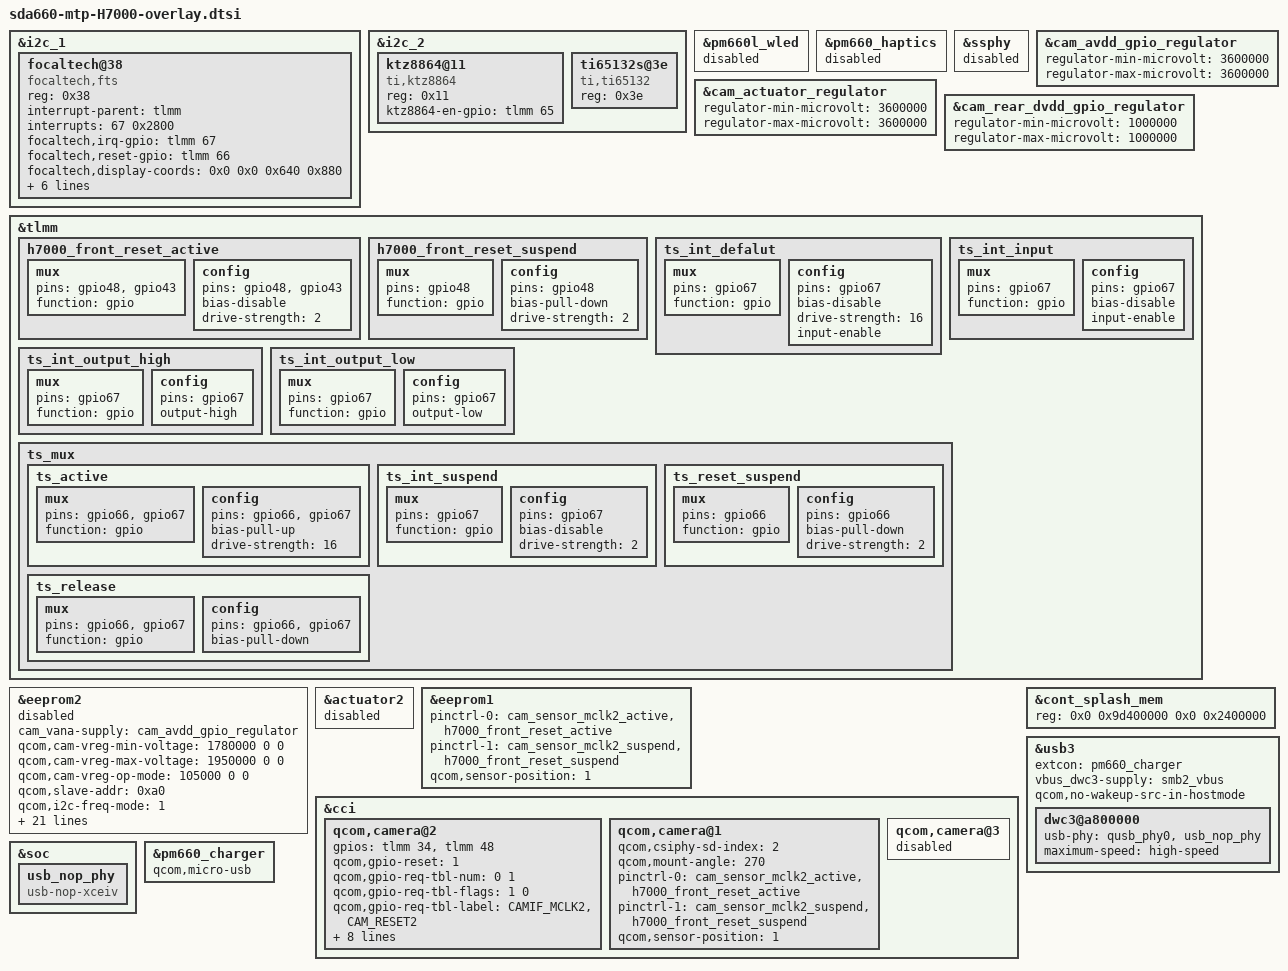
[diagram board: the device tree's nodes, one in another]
/*
 * SPDX-FileCopyrightText: The LineageOS Project
 * SPDX-License-Identifier: Apache-2.0
 */

#include "audio/sda660-audio-tfa98xxx.dtsi"
#include "battery/sda660-battery-H7000.dtsi"
#include "display/sda660-display-H7000.dtsi"

&i2c_1 {
	status = "ok";

	focaltech@38 {
		compatible = "focaltech,fts";
		reg = <0x38>;
		interrupt-parent = <&tlmm>;
		interrupts = <67 0x2800>;
		focaltech,irq-gpio = <&tlmm 67 0x2>;
		focaltech,reset-gpio = <&tlmm 66 0x0>;
		focaltech,display-coords = <0x0 0x0 0x640 0x880>;
		focaltech,max-touch-number = <10>;
		status = "okay";
		pinctrl-names = "pmx_ts_active", "pmx_ts_suspend", "pmx_ts_release";
		pinctrl-0 = <&ts_active>;
		pinctrl-1 = <&ts_int_suspend &ts_reset_suspend>;
		pinctrl-2 = <&ts_release>;
		vdd-supply = <&pm660l_l6>;
		vcc_i2c-supply = <&pm660_l13>;
	};
};

&i2c_2 {
	status = "ok";

	ktz8864@11 {
		compatible = "ti,ktz8864";
		reg = <0x11>;
		ktz8864-en-gpio = <&tlmm 65 0x0>;
	};

	ti65132s@3e {
		compatible = "ti,ti65132";
		reg = <0x3e>;
	};
};

&pm660l_wled {
	status = "disabled";
};

&pm660_haptics {
	status = "disabled";
};

&ssphy {
	status = "disabled";
};

&cam_avdd_gpio_regulator {
	regulator-min-microvolt = <3600000>;
	regulator-max-microvolt = <3600000>;
};

&cam_actuator_regulator {
	regulator-min-microvolt = <3600000>;
	regulator-max-microvolt = <3600000>;
};

&cam_rear_dvdd_gpio_regulator {
	regulator-min-microvolt = <1000000>;
	regulator-max-microvolt = <1000000>;
};

/* Front camera fix (v46): align camera@2/eeprom2 to stock h7000.dts
 * front cam (camera@1/eeprom@1): MCLK2 (gpio34), RESET2 (gpio48),
 * cci-master 1, CSIPHY2/CSID2, sensor-mode 1, mount-angle 270, NO VAF
 * and NO VANA gpio. Stock LOS used MCLK1(33)/RESET(47)gpio44(VANA)
 * gpio50(VAF) which are the rear2/iris pins - wrong for the H7000
 * front module, so the sensor never gets MCLK/RESET -> black frame. */
&tlmm {
	h7000_front_reset_active: h7000_front_reset_active {
		mux {
			pins = "gpio48", "gpio43";
			function = "gpio";
		};
		config {
			pins = "gpio48", "gpio43";
			bias-disable;
			drive-strength = <2>;
		};
	};
	h7000_front_reset_suspend: h7000_front_reset_suspend {
		mux {
			pins = "gpio48";
			function = "gpio";
		};
		config {
			pins = "gpio48";
			bias-pull-down;
			drive-strength = <2>;
		};
	};
};

&eeprom2 {
	cam_vana-supply = <&cam_avdd_gpio_regulator>;
	qcom,cam-vreg-min-voltage = <1780000 0 0>;
	qcom,cam-vreg-max-voltage = <1950000 0 0>;
	qcom,cam-vreg-op-mode = <105000 0 0>;
	qcom,slave-addr = <0xa0>;
	qcom,i2c-freq-mode = <1>;
	qcom,num-blocks = <1>;
	qcom,page0 = <0x00 0x00 0x02 0x00 0x01 0x00>;
	qcom,poll0 = <0x00 0x00 0x02 0x00 0x01 0x00>;
	qcom,mem0 = <0x14 0x00 0x02 0x00 0x01 0x00>;
	qcom,cam-power-seq-type = "sensor_vreg";
	qcom,cam-power-seq-val = "cam_vio";
	qcom,cam-power-seq-cfg-val = <1>;
	qcom,cam-power-seq-delay = <1>;
	status = "disabled";
	gpios = <&tlmm 34 0>,
		<&tlmm 48 0>;
	/delete-property/ qcom,gpio-vana;
	/delete-property/ qcom,gpio-vaf;
	qcom,gpio-reset = <1>;
	qcom,gpio-req-tbl-num = <0 1>;
	qcom,gpio-req-tbl-flags = <1 0>;
	qcom,gpio-req-tbl-label = "CAMIF_MCLK2",
			"CAM_RESET2";
	pinctrl-0 = <&cam_sensor_mclk2_active
			 &h7000_front_reset_active>;
	pinctrl-1 = <&cam_sensor_mclk2_suspend
			 &h7000_front_reset_suspend>;
	qcom,sensor-mode = <1>;
	clocks = <&clock_mmss MCLK2_CLK_SRC>,
		<&clock_mmss MMSS_CAMSS_MCLK2_CLK>;
	clock-names = "cam_src_clk", "cam_clk";
};

&actuator2 {
	/delete-property/ cam_vaf-supply;
	/delete-property/ qcom,cam-vreg-name;
	status = "disabled";
};

/* v53: camera@1/eeprom@1 must stay ALIVE - HAL camera_id 1 (s5k4h7,
 * camera_config.xml CameraId 1) maps to kernel ctrl[1] = camera@1.
 * Disabling it broke INIT_CFG (s_ctrl NULL, rc -22) and the front cam
 * never registered. LOS camera@1 is exactly the stock front-cam
 * resource (MCLK2/gpio34, RESET2/gpio48, CCI1, CSID2, cam_vana=GPIO51).
 * Align it fully to stock front (CSIPHY2, mount 270, position 1,
 * front pinctrl gpio48gpio43). eeprom@1 stays active for
 * camera@1->eeprom-src; eeprom@2 is disabled (not used by HAL, avoids
 * double-requesting gpio34/48 with eeprom1). */
&eeprom1 {
	pinctrl-0 = <&cam_sensor_mclk2_active
			 &h7000_front_reset_active>;
	pinctrl-1 = <&cam_sensor_mclk2_suspend
			 &h7000_front_reset_suspend>;
	qcom,sensor-position = <1>;
};

&cci {
	qcom,camera@2 {
		/delete-property/ qcom,actuator-src;
		/delete-property/ qcom,gpio-vana;
		/delete-property/ qcom,gpio-vaf;
		gpios = <&tlmm 34 0>,
			<&tlmm 48 0>;
		qcom,gpio-reset = <1>;
		qcom,gpio-req-tbl-num = <0 1>;
		qcom,gpio-req-tbl-flags = <1 0>;
		qcom,gpio-req-tbl-label = "CAMIF_MCLK2",
					"CAM_RESET2";
		pinctrl-0 = <&cam_sensor_mclk2_active
				 &h7000_front_reset_active>;
		pinctrl-1 = <&cam_sensor_mclk2_suspend
				 &h7000_front_reset_suspend>;
		qcom,sensor-mode = <1>;
		qcom,mount-angle = <270>;
		clocks = <&clock_mmss MCLK2_CLK_SRC>,
			<&clock_mmss MMSS_CAMSS_MCLK2_CLK>;
		clock-names = "cam_src_clk", "cam_clk";
	};

	/* v53: camera@1 is the stock front-cam resource node that HAL
	 * camera_id 1 maps to - keep it ACTIVE, fully aligned to stock
	 * front: CSIPHY2, mount-angle 270, sensor-position 1,
	 * pinctrl gpio48gpio43. camera@3 (iris) stays disabled. */
	qcom,camera@1 {
		qcom,csiphy-sd-index = <2>;
		qcom,mount-angle = <270>;
		pinctrl-0 = <&cam_sensor_mclk2_active
				 &h7000_front_reset_active>;
		pinctrl-1 = <&cam_sensor_mclk2_suspend
				 &h7000_front_reset_suspend>;
		qcom,sensor-position = <1>;
	};
	qcom,camera@3 {
		status = "disabled";
	};
};

&cont_splash_mem {
	reg = <0x0 0x9d400000 0x0 0x2400000>;
};

&usb3 {
    extcon = <&pm660_charger>;
	vbus_dwc3-supply = <&smb2_vbus>;
	qcom,no-wakeup-src-in-hostmode;
	
	dwc3@a800000 {
	    usb-phy = <&qusb_phy0>, <&usb_nop_phy>;
		maximum-speed = "high-speed";     
    };
};

&soc {
	usb_nop_phy: usb_nop_phy {
		compatible = "usb-nop-xceiv";
	};
};

&pm660_charger {
    qcom,micro-usb; // Fix usb
};

&tlmm {
	ts_int_defalut: ts_int_defalut {
		mux {
			pins = "gpio67";
			function = "gpio";
		};

		config {
			pins = "gpio67";
			bias-disable;
			drive-strength = <16>;
			input-enable;
		};
	};

	ts_int_input: ts_int_input {
		mux {
			pins = "gpio67";
			function = "gpio";
		};

		config {
			pins = "gpio67";
			bias-disable;
			input-enable;
		};
	};

	ts_int_output_high: ts_int_output_high {
		mux {
			pins = "gpio67";
			function = "gpio";
		};

		config {
			pins = "gpio67";
			output-high;
		};
	};

	ts_int_output_low: ts_int_output_low {
		mux {
			pins = "gpio67";
			function = "gpio";
		};

		config {
			pins = "gpio67";
			output-low;
		};
	};

	ts_mux {
		ts_active: ts_active {
			mux {
				pins = "gpio66", "gpio67";
				function = "gpio";
			};

			config {
				pins = "gpio66", "gpio67";
				bias-pull-up;
				drive-strength = <16>;
			};
		};

		ts_int_suspend: ts_int_suspend {
			mux {
				pins = "gpio67";
				function = "gpio";
			};

			config {
				pins = "gpio67";
				bias-disable;
				drive-strength = <2>;
			};
		};

		ts_reset_suspend: ts_reset_suspend {
			mux {
				pins = "gpio66";
				function = "gpio";
			};

			config {
				pins = "gpio66";
				bias-pull-down;
				drive-strength = <2>;
			};
		};

		ts_release: ts_release {
			mux {
				pins = "gpio66", "gpio67";
				function = "gpio";
			};

			config {
				pins = "gpio66", "gpio67";
				bias-pull-down;
			};
		};
	};
};
